# CEC1712H_S2_SX device description
Architecture: CORTEX-M4; Family: CEC1712H_S2_SX; Series: CEC1712H_S2_SX
Registers are 32-bit, read-write, reset 0x0 unless marked. A register's access mark holds for its fields unless they carry their own. Offsets are from the block's base; [hi:lo] are bit positions.

## DMA_MAIN — DMA Main Registers
Instances: DMA_MAIN 0x40002400
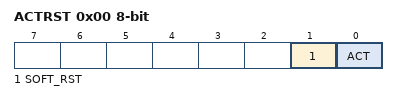
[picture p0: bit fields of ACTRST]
0x00 ACTRST 8-bit — Soft reset the entire module. Enable the blocks operation.
  [1] SOFT_RST — Soft reset the entire module. This bit is self-clearing.
  [0] ACT — Enable the blocks operation. (R/WS). 1=Enable block. Each individual channel must be enabled separately. 0=Disable all channels.
0x04 DATA_PKT ro — Debug register that has the data that is stored in the Data Packet. This data is read data from the currently active transfer source.

## GCR — The Logical Device Configuration registers support motherboard designs in which the resources required by their components are known and assigned by the BIOS at POST.
Instances: GCR 0x400FFF00
0x07 LDN 8-bit — A write to this register selects the current logical device. This allows access to the control and configuration registers for each logical device. Note: The Activate command operates only on the selected logical device.
0x1C DEV_REV 8-bit ro — A read-only register which provides device revision information.
0x1D DEV_SUBID 8-bit ro reset 0x52 — A read-only register which provides device sub ID information.
0x1E DEV_ID 16-bit ro reset 0x23 — A read-only register which provides device identification.
0x20 LEG_DEV_ID 8-bit ro reset 0xFE — A read-only register which provides legacy device identification.
0x21 LEG_DEV_REV 8-bit ro reset 0xA0 — A read-only register which provides legacy device revision information.

## WDT — The function of the Watchdog Timer is to provide a mechanism to detect if the internal embedded controller has failed.
Instances: WDT 0x40000400
0x00 LOAD 16-bit reset 0xFFFF — Writing this field reloads the Watch Dog Timer counter.
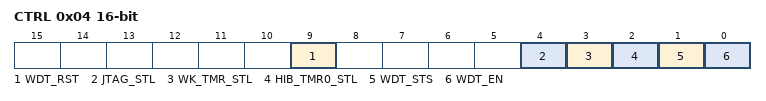
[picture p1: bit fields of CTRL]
0x04 CTRL 16-bit — WDT Control Register
  [9] WDT_RST — If the WDT_RESET bit is set and the watch dog timer expires, the Watch dog module will generate interrupt and clear the WDT_RESET to 0b.
  [4] JTAG_STL — This bit enables the WDT Stall function if JTAG or SWD debug functions are active. 1=The WDT is stalled while either JTAG or SWD is active. 0=The WDT is not affected by the JTAG debug interface.
  [3] WK_TMR_STL — This bit enables the WDT Stall function if the Week Timer is active. 1=The WDT is stalled while the Week Timer is active. 0=The WDT is not affected by the Week Timer.
  [2] HIB_TMR0_STL — This bit enables the WDT Stall function if the Hibernation Timer 0 is active. 1=The WDT is stalled while the Hibernation Timer 0 is active. 0=The WDT is not affected by Hibernation Timer 0.
  [1] WDT_STS — WDT_STATUS is set by hardware if the last reset of the device was caused by an underflow of the WDT. This bit must be cleared by the EC firmware writing a '1' to this bit. Writing a '0' to this bit has no effect.
  [0] WDT_EN — WDT Block enabled
0x08 KICK 8-bit wo — The WDT Kick Register is a strobe. Reads of this register return 0. Writes to this register cause the WDT to reload the WDT Load Register value and start decrementing when the WDT_ENABLE bit in the WDT Control Register is set to '1'. When the WDT_ENABLE bit in the WDT Control Register is cleared to '0', writes to the WDT Kick Register have no effect.
0x0C CNT 16-bit ro reset 0xFFFF — This read-only register provides the current WDT count.
0x10 STS 8-bit — This register provides the current WDT count.
  [0] WDT_EV_IRQ — WDT_EVENT_IRQ : This bit indicates the status of interrupt from Watch dog module.
0x14 IEN 8-bit — Watch Dog Interrupt Enable Register.
  [0] WDT_INTEN — WDT_Int_Enable: This is the interrupt enables bit for WDT_INT interrupt. 1= WDT_INT Interrupt Enable 0= WDT_INT Interrupt Disabled

## HTM — The Hibernation Timer can generate a wake event to the Embedded Controller (EC) when it is in a hibernation mode
Instances: HTM0 0x40009800, HTM1 0x40009820
0x00 PRLD 16-bit — [15:0] This register is used to set the Hibernation Timer Preload value.
0x04 CTRL 16-bit — HTimer Control Register
  [0] CTRL — 1= The Hibernation Timer has a resolution of 0.125s per LSB, which yields a maximum time in excess of 2 hours. 0= The Hibernation Timer has a resolution of 30.5us per LSB, which yields a maximum time of ~2seconds.
0x08 CNT 16-bit ro — The current state of the Hibernation Timer.
